# M3351 register map
File version: 1.0
Registers are 32-bit, read-write, reset 0x0 unless marked. A register's access mark holds for its fields unless they carry their own. Offsets are from the block's base; [hi:lo] are bit positions; {n}, {i} and the like mark numbered series.

## UART0 (part 2 of 2) — UART Register Map
Base 0x40070000
Same registers: UART{n} {0x40070000+0x1000*n} (n=1..9), UART{n}_NS {0x50070000+0x1000*n} (n=0..9)
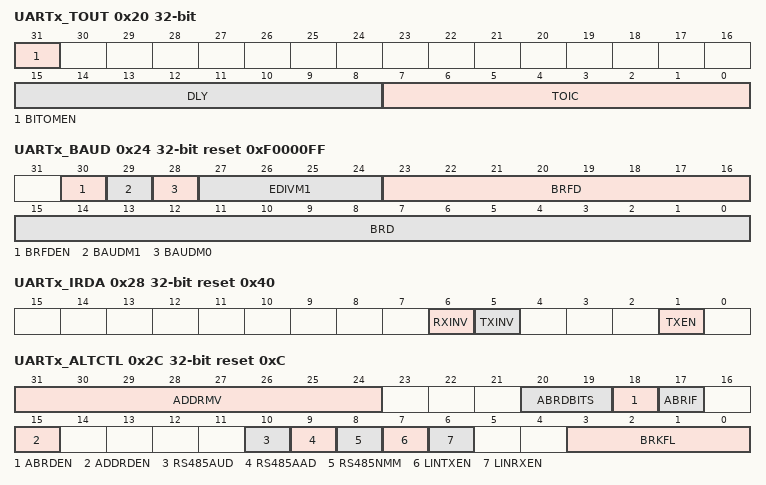
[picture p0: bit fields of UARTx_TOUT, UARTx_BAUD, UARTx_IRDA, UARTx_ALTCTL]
0x20 UARTx_TOUT — UART Time-out Register
  [31] BITOMEN — Bus Idle Time-out Mode Enable Bit. If BITOMEN (UART_TOUT[31]) is enabled, the reset conditions of the time-out counter and RXTOIF (UART_INTSTS[4]) will be changed to detect the bus idle. When BITOMEN (UART_TOUT[31]) is disabled, the time-out counter and RXTOIF (UART_INTSTS[4]) maintain reset value whenever the RX FIFO is empty. In addition, Any RX FIFO activities, such as a new incoming data or user reading data, will clear RXTOIF (UART_INTSTS[4]) and reset RX time-out counter.. On the other hand, when BITOMEN (UART_TOUT[31]) is enabled, the RX FIFO empty state will not reset the time-out counter and RXTOIF (UART_INTSTS[4]), and RX FIFO activities, such as a new incoming data or user reading data, will not clear RXTOIF (UART_INTSTS[4]). However, the time-out counter needs to receive a first incoming data before it can start counting. After receiving the first incoming data, the time-out counter will count even if the RX FIFO is empty.
    0=Bus idle time-out mode Disabled; 1=Bus idle time-out mode Enabled
  [15:8] DLY — TX Delay Time Value. This field is used to program the transfer delay time between the last STOP bit and next START bit. The unit is bit time.
  [7:0] TOIC — Time-out Interrupt Comparator
0x24 UARTx_BAUD reset 0xF0000FF — UART Baud Rate Divider Register
  [30] BRFDEN — Baud Rate Fractional Divider Enable Bit. Note: This bit has effect only at baud rate mode 2 (BAUDM1 (UART_BAUD[29]) and BAUDM0 (UART_BAUD[28]) must be 1).
    0=Baud Rate Fractional Divider Disabled; 1=Baud Rate Fractional Divider Enabled
  [29] BAUDM1 — BAUD Rate Mode Selection Bit 1. This bit is baud rate mode selection bit 1. UART provides three baud rate calculation modes. This bit combines with BAUDM0 (UART_BAUD[28]) to select baud rate calculation mode. The detail description is shown in Table 6.214. Note: In IrDA mode must be operated in mode 0.
  [28] BAUDM0 — BAUD Rate Mode Selection Bit 0. This bit is baud rate mode selection bit 0. UART provides three baud rate calculation modes. This bit combines with BAUDM1 (UART_BAUD[29]) to select baud rate calculation mode. The detail description is shown in Table 6.214.
  [27:24] EDIVM1 — Extra Divider for BAUD Rate Mode 1. This field is used for baud rate calculation in mode 1 and has no effect for baud rate calculation in mode 0 and mode 2. The detail description is shown in Table 6.214.
  [23:16] BRFD — Baud Rate Fractional Divider. This field is the fractional part of the baud rate divisor. When BRFDEN (UART_BAUD[30]) is set, the Baud Rate Equation goes to UART_CLK / ((BRD+2) + (BRFD/256)).
  [15:0] BRD — Baud Rate Divider. The field indicates the baud rate divider. This filed is used in baud rate calculation. The detail description is shown in Table 6.214.
0x28 UARTx_IRDA reset 0x40 — UART IrDA Control Register
  [6] RXINV — IrDA Inverse Receive Input Signal. Note 1: Before setting this bit, TXRXDIS (UART_FUNCSEL[3]) should be set then waited for TXRXACT (UART_FIFOSTS[31]) is cleared. When the configuration is done, cleared TXRXDIS (UART_FUNCSEL[3]) to activate UART controller. Note 2: This bit is valid when FUNCSEL (UART_FUNCSEL[2:0]) is select IrDA function.
    0=None inverse receiving input signal; 1=Inverse receiving input signal. (Default)
  [5] TXINV — IrDA Inverse Transmitting Output Signal. Note 1: Before setting this bit, TXRXDIS (UART_FUNCSEL[3]) should be set then waited for TXRXACT (UART_FIFOSTS[31]) is cleared. When the configuration is done, cleared TXRXDIS (UART_FUNCSEL[3]) to activate UART controller. Note 2: This bit is valid when FUNCSEL (UART_FUNCSEL[2:0]) is select IrDA function.
    0=None inverse transmitting signal. (Default); 1=Inverse transmitting output signal
  [1] TXEN — IrDA Receiver/Transmitter Selection Enable Bit
    0=IrDA Transmitter Disabled and Receiver Enabled. (Default); 1=IrDA Transmitter Enabled and Receiver Disabled
0x2C UARTx_ALTCTL reset 0xC — UART Alternate Control/Status Register
  [31:24] ADDRMV — Address Match Value. This field contains the RS-485 address match values. Note: This field is used for RS-485 auto address detection mode.
  [20:19] ABRDBITS — Auto-baud Rate Detect Bit Length. Note: The calculation of bit number includes the START bit.
    0=1-bit time from START bit to the 1st rising edge. The input pattern shall be 0x01; 1=2-bit time from START bit to the 1st rising edge. The input pattern shall be 0x02; 2=4-bit time from START bit to the 1st rising edge. The input pattern shall be 0x08; 3=8-bit time from START bit to the 1st rising edge. The input pattern shall be 0x80
  [18] ABRDEN — Auto-baud Rate Detect Enable Bit. Note: This bit is cleared automatically after auto-baud detection is finished.
    0=Auto-baud rate detect function Disabled; 1=Auto-baud rate detect function Enabled
  [17] ABRIF — Auto-baud Rate Interrupt Flag (Read Only). This bit is set when auto-baud rate detection function finished or the auto-baud rate counter was overflow and if ABRIEN(UART_INTEN[18]) is set then the auto-baud rate interrupt will be generated. Note: This bit is read only, but it can be cleared by writing '1' to ABRDTOIF (UART_FIFOSTS[2]) and ABRDIF(UART_FIFOSTS[1]).
    0=No auto-baud rate interrupt flag is generated; 1=Auto-baud rate interrupt flag is generated
  [15] ADDRDEN — RS-485 Address Detection Enable Bit. This bit is used to enable RS-485 Address Detection mode. Note: This bit is used for RS-485 any operation mode.
    0=Address detection mode Disabled; 1=Address detection mode Enabled
  [10] RS485AUD — RS-485 Auto Direction Function. Note: It can be active with RS-485_AAD or RS-485_NMM operation mode.
    0=RS-485 Auto Direction Operation function (AUD) Disabled; 1=RS-485 Auto Direction Operation function (AUD) Enabled
  [9] RS485AAD — RS-485 Auto Address Detection Operation Mode. Note: It cannot be active with RS-485_NMM operation mode.
    0=RS-485 Auto Address Detection Operation mode (AAD) Disabled; 1=RS-485 Auto Address Detection Operation mode (AAD) Enabled
  [8] RS485NMM — RS-485 Normal Multi-drop Operation Mode. Note: It cannot be active with RS-485_AAD operation mode.
    0=RS-485 Normal Multi-drop Operation mode (NMM) Disabled; 1=RS-485 Normal Multi-drop Operation mode (NMM) Enabled
  [7] LINTXEN — LIN TX Break Mode Enable Bit. Note: When TX break field transfer operation finished, this bit will be cleared automatically.
    0=LIN TX Break mode Disabled; 1=LIN TX Break mode Enabled
  [6] LINRXEN — LIN RX Enable Bit
    0=LIN RX mode Disabled; 1=LIN RX mode Enabled
  [3:0] BRKFL — UART LIN Break Field Length. This field indicates a 4-bit LIN TX break field count. Note 1: This break field length is BRKFL + 1.
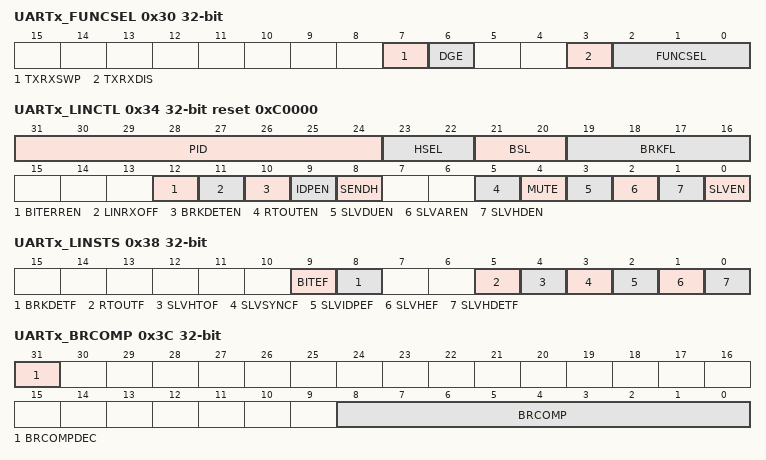
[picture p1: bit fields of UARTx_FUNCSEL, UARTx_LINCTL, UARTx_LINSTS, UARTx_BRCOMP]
0x30 UARTx_FUNCSEL — UART Function Select Register
  [7] TXRXSWP — TX and RX Swap Enable Bit. Setting this bit Swaps TX pin and RX pin.
    0=TX and RX Swap Disabled; 1=TX and RX Swap Enabled
  [6] DGE — Deglitch Enable Bit. Note 1: When this bit is set to logic 1, any pulse width less than about 150 ns will be considered a glitch and will be removed in the serial data input (RX). This bit acts only on RX line and has no effect on the transmitter logic. Note 2: It is recommended to set this bit only when operating at baud rate under 2.5 Mbps.
    0=Deglitch Disabled; 1=Deglitch Enabled
  [3] TXRXDIS — TX and RX Disable Bit. Setting this bit can disable TX and RX. Note: The TX and RX will not be disabled immediately when this bit is set. The TX and RX complete current task before TX and RX are disabled. When TX and RX are disabled, the TXRXACT (UART_FIFOSTS[31]) is cleared.
    0=TX and RX Enabled; 1=TX and RX Disabled
  [2:0] FUNCSEL — Function Select
    0=UART function; 1=LIN function; 2=IrDA function; 3=RS-485 function; 4=UART Single-wire function
0x34 UARTx_LINCTL reset 0xC0000 — UART LIN Control Register
  [31:24] PID — LIN PID Bits. If the parity generated by hardware, user fill ID0~ID5 (PID[29:24]), hardware will calculate P0 (PID[30]) and P1 (PID[31]), otherwise user must filled frame ID and parity in this field. Note 1: User can fill any 8-bit value to this field and the bit 24 indicates ID0 (LSB first). Note 2: This field can be used for LIN master mode or slave mode.
  [23:22] HSEL — LIN Header Select
    0=The LIN header includes 'break field'; 1=The LIN header includes 'break field' and 'sync field'; 2=The LIN header includes 'break field', 'sync field' and 'frame ID field'
  [21:20] BSL — LIN Break/Sync Delimiter Length. Note: This bit used for LIN master to sending header field.
    {v}=The LIN break/sync delimiter length is {v+1}-bit time (v=0..3)
  [19:16] BRKFL — LIN Break Field Length. This field indicates a 4-bit LIN TX break field count. Note 1: These registers are shadow registers of BRKFL (UART_ALTCTL[3:0]). User can read/write it by setting BRKFL (UART_ALTCTL[3:0]) or BRKFL (UART_LINCTL[19:16]). Note 2: This break field length is BRKFL + 1.
  [12] BITERREN — Bit Error Detect Enable Bit
    0=Bit error detection function Disabled; 1=Bit error detection function Enabled
  [11] LINRXOFF — LIN Receiver Disable Bit
    0=LIN receiver Enabled; 1=LIN receiver Disabled
  [10] BRKDETEN — LIN Break Detection Enable Bit
    0=LIN break detection Disabled; 1=LIN break detection Enabled
  [9] IDPEN — LIN ID Parity Enable Bit
    0=LIN frame ID parity Disabled; 1=LIN frame ID parity Enabled
  [8] SENDH — LIN TX Send Header Enable Bit. The LIN TX header can be 'break field' or 'break and sync field' or 'break, sync and frame ID field', it is depend on setting HSEL (UART_LINCTL[23:22]). Note 1: This bit is shadow bit of LINTXEN (UART_ALTCTL[7]); user can read/write it by setting LINTXEN (UART_ALTCTL[7]) or SENDH (UART_LINCTL[8]). Note 2: When transmitter header field (it may be 'break' or 'break + sync' or 'break + sync + frame ID' selected by HSEL (UART_LINCTL[23:22]) field) transfer operation finished, this bit will be cleared automatically.
    0=Send LIN TX header Disabled; 1=Send LIN TX header Enabled
  [5] RTOUTEN — LIN Response Time-out Detection Enable Bit
    0=LIN response time-out detection Disabled; 1=LIN response time-out detection Enabled
  [4] MUTE — LIN Mute Mode Enable Bit. Note: The exit from mute mode condition and each control and interactions of this field are explained in 6.21.5.10 (LIN slave mode).
    0=LIN mute mode Disabled; 1=LIN mute mode Enabled
  [3] SLVDUEN — LIN Slave Divider Update Method Enable Bit. Note 2: This bit used for LIN Slave Automatic Resynchronization mode. (for Non-Automatic Resynchronization mode, this bit should be kept cleared). Note 3: The control and interactions of this field are explained in 6.21.5.10 (Slave mode with automatic resynchronization).
    0=UART_BAUD updated is written by software (if no automatic resynchronization update occurs at the same time); 1=UART_BAUD is updated at the next received character. User must set the bit before checksum reception
  [2] SLVAREN — LIN Slave Automatic Resynchronization Mode Enable Bit. Note 2: When operation in Automatic Resynchronization mode, the baud rate setting must be mode 2 (BAUDM1 (UART_BAUD[29]) and BAUDM0 (UART_BAUD[28]) must be 1). Note 3: The control and interactions of this field are explained in 6.21.5.10 (Slave mode with automatic resynchronization). Note 4: The minimum detection range of the target BRD (UART_BAUD[15:0]) is 0x30.
    0=LIN automatic resynchronization Disabled; 1=LIN automatic resynchronization Enabled
  [1] SLVHDEN — LIN Slave Header Detection Enable Bit
    0=LIN slave header detection Disabled; 1=LIN slave header detection Enabled
  [0] SLVEN — LIN Slave Mode Enable Bit
    0=LIN slave mode Disabled; 1=LIN slave mode Enabled
0x38 UARTx_LINSTS — UART LIN Status Register
  [9] BITEF — Bit Error Detect Status Flag. At TX transfer state, hardware will monitor the bus state, if the input pin (UART_RXD) state not equals to the output pin (UART_TXD) state, BITEF (UART_LINSTS[9]) will be set.
    0=Bit error not detected; 1=Bit error detected
  [8] BRKDETF — LIN Break Detection Flag. This bit is set by hardware when a break is detected and be cleared by writing 1 to it through software.
    0=LIN break not detected; 1=LIN break detected
  [5] RTOUTF — LIN Response Time-out Flag. This bit is set when no LIN response received and the time-out counter equal to or bigger than LINRTOIC (UART_LINRTOUT[23:0]). If LINIEN (UART_INTEN[8]) is enabled, the LIN Bus Interrupt will be generated. Note 1: This bit can be cleared by writing 1 to it.
    0=LIN response time-out not detected; 1=LIN response time-out detected
  [4] SLVHTOF — LIN Slave Header Time-out Flag. This bit is set by hardware when a LIN header reception time-out is detected in LIN slave mode and be cleared by writing 1 to it. When this bit is set, SLVHEF (UART_LINSTS[1]) will also be set.
    0=LIN header time-out not detected; 1=LIN header time-out detected
  [3] SLVSYNCF — LIN Slave Sync Field. This bit indicates that the LIN sync field is being analyzed in Automatic Resynchronization mode. When the receiver header have some error been detect, user must reset the internal circuit to re-search new frame header by writing 1 to this bit. Note 2: This bit can be cleared by writing 1 to it. Note 3: When writing 1 to it, hardware will reload the initial baud rate and re-search a new frame header.
    0=The current character is not at LIN sync state; 1=The current character is at LIN sync state
  [2] SLVIDPEF — LIN Slave ID Parity Error Flag. This bit is set by hardware when receipted frame ID parity is not correct.
    0=No active; 1=Receipted frame ID parity is not correct
  [1] SLVHEF — LIN Slave Header Error Flag. This bit is set by hardware when a LIN header error is detected in LIN slave mode and be cleared by writing 1 to it. The header errors include 'break delimiter is too short (less than 0.5 bit time)', 'frame error in sync field or Identifier field', 'sync field data is not 0x55 in Non-Automatic Resynchronization mode', 'sync field deviation error with Automatic Resynchronization mode', 'sync field measure time-out with Automatic Resynchronization mode' and 'LIN header reception time-out'.
    0=LIN header error not detected; 1=LIN header error detected
  [0] SLVHDETF — LIN Slave Header Detection Flag. This bit is set by hardware when a LIN header is detected in LIN slave mode and be cleared by writing 1 to it. Note 3: When enable ID parity check IDPEN (UART_LINCTL[9]), if hardware detect complete header ('break + sync + frame ID'), the SLVHDETF will be set whether the frame ID correct or not.
    0=LIN header not detected; 1=LIN header detected (break + sync + frame ID)
0x3C UARTx_BRCOMP — UART Baud Rate Compensation Register
  [31] BRCOMPDEC — Baud Rate Compensation Decrease
    0=Positive (increase one module clock) compensation for each compensated bit; 1=Negative (decrease one module clock) compensation for each compensated bit
  [8:0] BRCOMP — Baud Rate Compensation Patten. These 9-bits are used to define the relative bit is compensated or not. BRCOMP[7:0] is used to define the compensation of DAT (UART_DAT[7:0]) and BRCOM[8] is used to define PARITY (UART_DAT[8]).
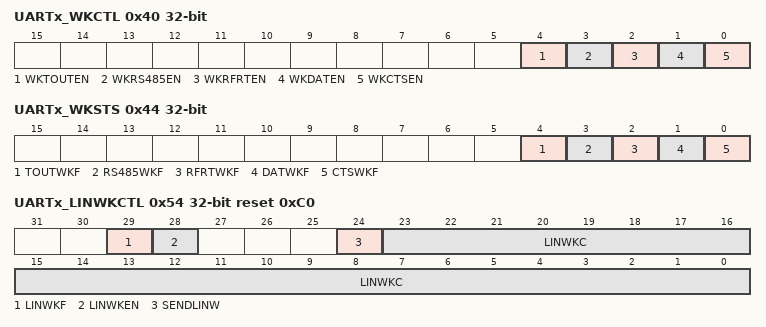
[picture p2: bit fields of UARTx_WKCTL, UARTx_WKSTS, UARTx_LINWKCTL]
0x40 UARTx_WKCTL — UART Wake-up Control Register
  [4] WKTOUTEN — Received Data FIFO Reached Threshold Time-out Wake-up Enable Bit. Note 1: When the system is in Power-down mode, Received Data FIFO reached threshold time-out will wake up system from Power-down mode. Note 2: It is suggested the function is enabled when the WKRFRTEN (UART_WKCTL[2]) is set to 1.
    0=Received Data FIFO reached threshold time-out wake-up system function Disabled; 1=Received Data FIFO reached threshold time-out wake-up system function Enabled
  [3] WKRS485EN — RS-485 Address Match Wake-up Enable Bit. Note 1: When the system is in Power-down mode, RS-485 Address Match will wake-up system from Power-down mode. Note 2: This bit is used for RS-485 Auto Address Detection (AAD) mode in RS-485 function mode and ADDRDEN (UART_ALTCTL[15]) is set to 1.
    0=RS-485 Address Match (AAD mode) wake-up system function Disabled; 1=RS-485 Address Match (AAD mode) wake-up system function Enabled
  [2] WKRFRTEN — Received Data FIFO Reached Threshold Wake-up Enable Bit. Note: When the system is in Power-down mode, Received Data FIFO reached threshold will wake-up system from Power-down mode.
    0=Received Data FIFO reached threshold wake-up system function Disabled; 1=Received Data FIFO reached threshold wake-up system function Enabled
  [1] WKDATEN — Incoming Data Wake-up Enable Bit. Note: When the system is in Power-down mode, incoming data will wake-up system from Power-down mode.
    0=Incoming data wake-up system function Disabled; 1=Incoming data wake-up system function Enabled
  [0] WKCTSEN — nCTS Wake-up Enable Bit. Note: When the system is in Power-down mode, an external nCTS change will wake up system from Power-down mode.
    0=nCTS Wake-up system function Disabled; 1=nCTS Wake-up system function Enabled
0x44 UARTx_WKSTS — UART Wake-up Status Register
  [4] TOUTWKF — Received Data FIFO Threshold Time-out Wake-up Flag. This bit is set if chip wake-up from power-down state by Received Data FIFO Threshold Time-out wake-up. Note 1: If WKTOUTEN (UART_WKCTL[4]) is enabled, the Received Data FIFO reached threshold time-out wake-up cause this bit is set to '1'. Note 2: This bit can be cleared by writing '1' to it.
    0=Chip stays in power-down state; 1=Chip wake-up from power-down state by Received Data FIFO reached threshold time-out wake-up
  [3] RS485WKF — RS-485 Address Match Wake-up Flag. This bit is set if chip wake-up from power-down state by RS-485 Address Match (AAD mode). Note 1: If WKRS485EN (UART_WKCTL[3]) is enabled, the RS-485 Address Match (AAD mode) wake-up cause this bit is set to '1'. Note 2: This bit can be cleared by writing '1' to it.
    0=Chip stays in power-down state; 1=Chip wake-up from power-down state by RS-485 Address Match (AAD mode) wake-up
  [2] RFRTWKF — Received Data FIFO Reached Threshold Wake-up Flag. This bit is set if chip wake-up from power-down state by Received Data FIFO reached threshold wake-up. Note 1: If WKRFRTEN (UART_WKCTL[2]) is enabled, the Received Data FIFO Reached Threshold wake-up cause this bit is set to '1'. Note 2: This bit can be cleared by writing '1' to it.
    0=Chip stays in power-down state; 1=Chip wake-up from power-down state by Received Data FIFO Reached Threshold wake-up
  [1] DATWKF — Incoming Data Wake-up Flag. This bit is set if chip wake-up from power-down state by data wake-up. Note 1: If WKDATEN (UART_WKCTL[1]) is enabled, the Incoming Data wake-up cause this bit is set to '1'. Note 2: This bit can be cleared by writing '1' to it.
    0=Chip stays in power-down state; 1=Chip wake-up from power-down state by Incoming Data wake-up
  [0] CTSWKF — nCTS Wake-up Flag. This bit is set if chip wake-up from power-down state by nCTS wake-up. Note 1: If WKCTSEN (UART_WKCTL[0]) is enabled, the nCTS wake-up cause this bit is set to '1'. Note 2: This bit can be cleared by writing '1' to it.
    0=Chip stays in power-down state; 1=Chip wake-up from power-down state by nCTS wake-up
0x48 UARTx_DWKCOMP — UART Incoming Data Wake-up Compensation Register
  [15:0] STCOMP — START Bit Compensation Value. These bits field indicate how many clock cycle selected by UART_CLK do the UART controller can get the 1st bit (START bit) when the device is wake-up from Power-down mode. Note: It is valid only when WKDATEN (UART_WKCTL[1]) is set.
0x4C UARTx_RS485DD — UART RS485 Transceiver Deactivate Delay Register
  [15:0] RTSDDLY — RS485 Transceiver Deactivate Delay Value. These bits field indicate how many clock cycles selected by UART_CLK do the UART controller delay the RS485 transceiver state trancing when the state trancing of RS485 transceiver is from TX to RX state. These bits field have no effect when the state trancing of RS485 transceiver is from RX to TX state. Note: It is valid only when RS485AUD (UART_ALTCTL[10]) is set.
0x50 UARTx_LINRTOUT reset 0xFFFFFF — UART LIN Response Time-out Register
  [23:0] LINRTOIC — LIN Response Time-out Comparator
0x54 UARTx_LINWKCTL reset 0xC0 — UART LIN Wake-up Control Register
  [29] LINWKF — LIN Wake-up Flag. This bit is set if chip wake-up from power-down state by LIN wake-up. Note 1: If LINWKEN (UART_LINWKCTL[28]) is enabled, the LIN wake-up event will cause this bit set to '1'. Note 2: This bit can be cleared by writing '1' to it.
    0=Chip stays in power-down state; 1=Chip wake-up from power-down state by LIN wake-up
  [28] LINWKEN — LIN Wake-up Enable Bit. Note 1: When the system is in Power-down mode, LIN wake-up event will wake up system from Power-down mode.
    0=LIN wake-up system function Disabled; 1=LIN wake-up system function Enabled
  [24] SENDLINW — LIN Send Wake-up Enable Bit. Note 1: When this bit is set, the UART will send LIN wake-up automatically. When LIN wake-up transfer operation finished, this bit will be cleared automatically.
    0=Send LIN Wake-up Disabled; 1=Send LIN Wake-up Enabled
  [23:0] LINWKC — LIN Send Wake-up Signal Length Counter
